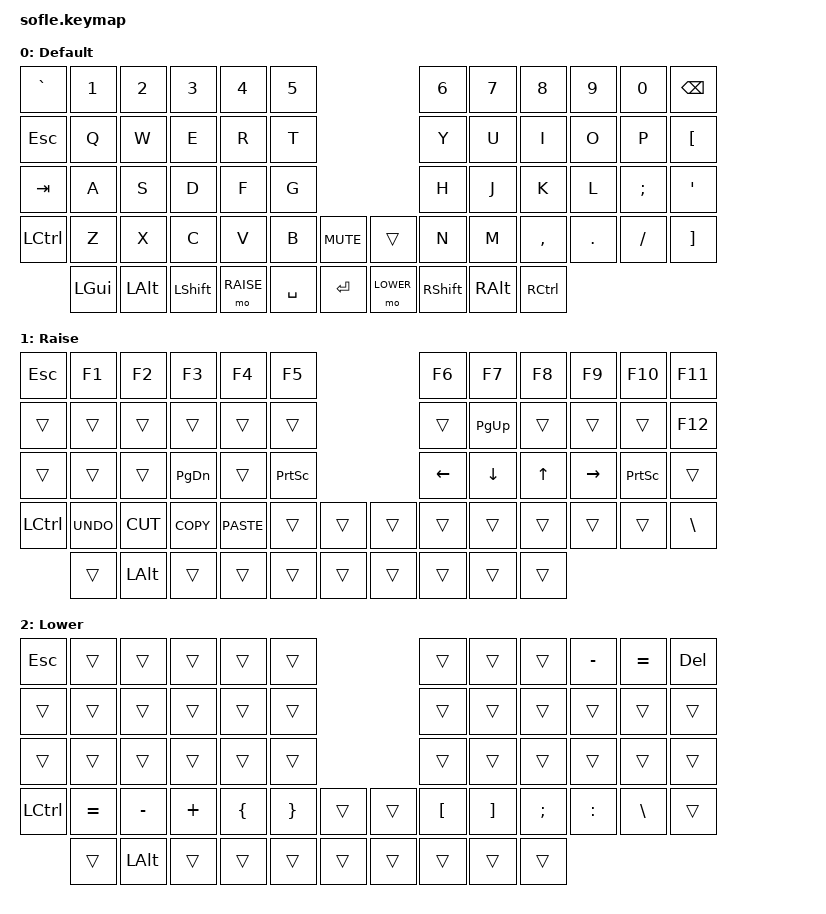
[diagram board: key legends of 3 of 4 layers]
/*
 * Copyright (c) 2020 The ZMK Contributors
 *
 * SPDX-License-Identifier: MIT
 */

#include <behaviors.dtsi>
#include <dt-bindings/zmk/keys.h>
#include <dt-bindings/zmk/bt.h>
#include <dt-bindings/zmk/rgb.h>
#include <dt-bindings/zmk/ext_power.h>

#define BASE 0
#define LOWER 2
#define RAISE 1
#define ADJUST 3

/ {
    // Активация слоя ADJUST при одновременном нажатии LOWER и RAISE
    conditional_layers {
        compatible = "zmk,conditional-layers";
        tri_layer {
            if-layers = <RAISE LOWER>;
            then-layer = <ADJUST>;
        };
    };

    keymap {
        compatible = "zmk,keymap";

        default_layer {
            display-name = "Default";
            bindings = <
                &kp GRAVE   &kp N1    &kp N2    &kp N3    &kp N4    &kp N5                      &kp N6    &kp N7    &kp N8    &kp N9    &kp N0    &kp BSPC
                &kp ESC     &kp Q     &kp W     &kp E     &kp R     &kp T                       &kp Y     &kp U     &kp I     &kp O     &kp P     &kp LBKT
                &kp TAB     &kp A     &kp S     &kp D     &kp F     &kp G                       &kp H     &kp J     &kp K     &kp L     &kp SEMI  &kp QUOT
                &kp LCTRL   &kp Z     &kp X     &kp C     &kp V     &kp B     &kp C_MUTE &trans &kp N     &kp M     &kp COMMA &kp DOT   &kp FSLH  &kp RBKT
                                 &kp LGUI &kp LALT &kp LSHFT &mo RAISE &kp SPACE &kp RET &mo LOWER &kp RSHFT &kp RALT &kp RCTRL
            >;

            sensor-bindings = <&inc_dec_kp C_VOL_UP C_VOL_DN &inc_dec_kp PG_UP PG_DN>;
        };

        raise_layer {
            display-name = "Raise";
            bindings = <
                &kp ESC     &kp F1    &kp F2    &kp F3    &kp F4    &kp F5                      &kp F6    &kp F7    &kp F8    &kp F9    &kp F10   &kp F11
                &trans      &trans    &trans    &trans    &trans    &trans                      &trans    &kp PG_UP &trans    &trans    &trans    &kp F12
                &trans      &trans    &trans    &kp PG_DN &trans    &kp PRINTSCREEN             &kp LEFT  &kp DOWN  &kp UP    &kp RIGHT &kp PRINTSCREEN &trans
                &kp LCTRL   &kp K_UNDO &kp K_CUT &kp K_COPY &kp K_PASTE &trans &trans &trans    &trans    &trans    &trans    &trans    &trans    &kp BSLH
                                 &trans &kp LALT &trans &trans &trans &trans &trans &trans &trans &trans
            >;

            sensor-bindings = <&inc_dec_kp C_VOL_UP C_VOL_DN &inc_dec_kp PG_UP PG_DN>;
        };

        lower_layer {
            display-name = "Lower";
            bindings = <
                &kp ESC     &trans    &trans    &trans    &trans    &trans                      &trans    &trans    &trans    &kp MINUS &kp EQUAL &kp DEL
                &trans      &trans    &trans    &trans    &trans    &trans                      &trans    &trans    &trans    &trans    &trans    &trans
                &trans      &trans    &trans    &trans    &trans    &trans                      &trans    &trans    &trans    &trans    &trans    &trans
                &kp LCTRL   &kp EQUAL &kp MINUS &kp PLUS  &kp LBRC  &kp RBRC &trans &trans      &kp LBKT  &kp RBKT  &kp SEMI  &kp COLON &kp BSLH  &trans
                                 &trans &kp LALT &trans &trans &trans &trans &trans &trans &trans &trans
            >;

            sensor-bindings = <&inc_dec_kp C_VOL_UP C_VOL_DN &inc_dec_kp PG_UP PG_DN>;
        };

        adjust_layer {
            display-name = "Adjust";
            bindings = <
                &bt BT_CLR        &bt BT_SEL 0    &bt BT_SEL 1    &bt BT_SEL 2    &bt BT_SEL 3    &bt BT_SEL 4                      &trans &trans &trans &trans &trans &trans
                &ext_power EP_TOG &rgb_ug RGB_HUD &rgb_ug RGB_HUI &rgb_ug RGB_SAD &rgb_ug RGB_SAI &rgb_ug RGB_EFF                   &trans &trans &trans &trans &trans &trans
                &trans            &rgb_ug RGB_BRD &rgb_ug RGB_BRI &trans          &trans          &trans                            &trans &trans &trans &trans &trans &trans
                &kp LCTRL         &trans          &trans          &trans          &trans          &trans          &rgb_ug RGB_TOG &trans &trans &trans &trans &trans &trans
                                 &trans &trans &trans &trans &trans &trans &trans &trans &trans &trans
            >;
        };
    };
};

